# PIC18LF6393 register map
Vendor: Microchip
Architecture 18xxxx. Special function registers and configuration words.
Registers are 8-bit, read-write, no defined reset value unless marked. A register's access mark holds for its fields unless they carry their own. Addresses are absolute, and some are shared; only a register's first bit layout is shown; lines under a group give offsets from that group; [hi:lo] are bit positions; {n}, {i} and the like mark numbered series; 'fields as' and 'values as' point back to an identical list; <NAME> marks a mode.

## Further device data
pins=1: LCDBIAS2; 2: LCDBIAS1; 3: RG0/SEG30; 4: RG1/TX2/CK2/SEG29; 5: RG2/RX2/DT2/SEG28; 6: RG3/SEG27; 7: MCLR/Vpp/RG5; 8: RG4/SEG26; 9: Vss; 10: Vdd; 11: RF7/SS/SEG25; 12: RF6/AN11/SEG24; 13: RF5/AN10/CVref/SEG23; 14: RF4/AN9/SEG22; 15: RF3/AN8/SEG21; 16: RF2/AN7/C1OUT/SEG20; 17: RF1/AN6/C2OUT/SEG19; 18: RF0/AN5/SEG18; 19: AVdd; 20: AVss; 21: RA3/AN3/Vref+/SEG17; 22: RA2/AN2/Vref-/SEG16; 23: RA1/AN1; 24: RA0/AN0; 25: Vss; 26: Vdd; 27: RA5/AN4/HLVDIN/SEG15; 28: RA4/T0CKI/SEG14; 29: RC1/T1OSI/CCP2; 30: RC0/T1OSO/T13CKI; 31: RC6/TX1/CK1; 32: RC7/RX1/DT1; 33: RC2/CCP1/SEG13; 34: RC3/SCK/SCL; 35: RC4/SDI/SDA; 36: RC5/SDO/SEG12; 37: RB7/KBI3/PGD; 38: Vdd; 39: OSC1/CLKI/RA7; 40: OSC2/CLKO/RA6; 41: Vss; 42: RB6/KBI2/PGC; 43: RB5/KBI1; 44: RB4/KBI0/SEG11; 45: RB3/INT3/SEG10; 46: RB2/INT2/SEG9; 47: RB1/INT1/SEG8; 48: RB0/INT0; 49: RD7/SEG7; 50: RD6/SEG6; 51: RD5/SEG5; 52: RD4/SEG4; 53: RD3/SEG3; 54: RD2/SEG2; 55: RD1/SEG1; 56: Vss; 57: Vdd; 58: RD0/SEG0; 59: RE7/CCP2/SEG31; 60: RE6/COM3; 61: RE5/COM2; 62: RE4/COM1; 63: COM0; 64: LCDBIAS3

## CONFIG — Configuration words, addresses in ProgramSpace
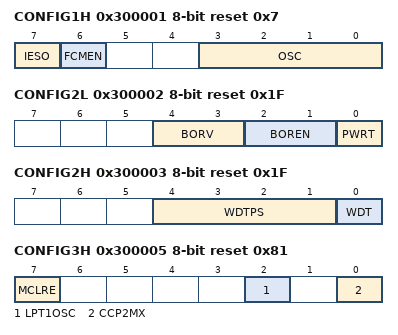
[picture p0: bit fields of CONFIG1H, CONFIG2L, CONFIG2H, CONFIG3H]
0x300001 CONFIG1H reset 0x7
  [7] IESO — Internal External Switch Over Mode
    0=OFF (Oscillator Switchover mode disabled); 1=ON (Oscillator Switchover mode enabled)
  [6] FCMEN — Fail-Safe Clock Monitor Enable
    0=OFF (Fail-Safe Clock Monitor disabled); 1=ON (Fail-Safe Clock Monitor enabled)
  [3:0] OSC — Oscillator
    0b11xx=11XX EXT RC-CLKOUT on RA6; 0b101x=101X EXT RC-CLKOUT on RA6; 9=INTIO7 (Internal oscillator block, CLKO function on RA6, port function on RA7); 8=INTIO67 (Internal oscillator block, port function on RA6 and RA7); 7=RCIO (External RC oscillator, port function on RA6); 6=HSPLL (HS oscillator, PLL enabled (clock frequency = 4 x FOSC1)); 5=ECIO (EC oscillator, port function on RA6); 4=EC (EC oscillator, CLKO function on RA6); 3=RC (External RC oscillator, CLKO function on RA6); 2=HS (HS oscillator); 1=XT (XT oscillator); 0=LP (LP oscillator)
0x300002 CONFIG2L reset 0x1F
  [4:3] BORV — Brown Out Voltage
    3=VBOR set to 2.1V; 2=VBOR set to 2.8V; 1=VBOR set to 4.3V; 0=VBOR set to 4.6V
  [2:1] BOREN — Brown Out Detect
    3=SBORDIS (Brown-out Reset enabled in hardware only (SBOREN is disabled)); 2=NOSLP (Brown-out Reset enabled in hardware only and disabled in Sleep mode (SBOREN is disabled)); 1=ON (Brown-out Reset enabled and controlled by software (SBOREN is enabled)); 0=OFF (Brown-out Reset disabled in hardware and software)
  [0] PWRT — Power Up Timer
    1=OFF (PWRT disabled); 0=ON (PWRT enabled)
0x300003 CONFIG2H reset 0x1F
  [4:1] WDTPS — Watchdog Postscaler
    15=1:32768; 14=1:16384; 13=1:8192; 12=1:4096; 11=1:2048; 10=1:1024; 9=1:512; 8=1:256; 7=1:128; 6=1:64; 5=1:32; 4=1:16; 3=1:8; 2=1:4; 1=1:2; 0=1:1
  [0] WDT — Watchdog Timer
    1=ON (WDT enabled); 0=OFF (WDT disabled (control is placed on the SWDTEN bit))
0x300004 CONFIG3L reset 0xFF
0x300005 CONFIG3H reset 0x81
  [7] MCLRE — Master Clear Enable
    1=ON (MCLR pin enabled; RG5 input pin disabled); 0=OFF (RG5 input pin enabled; MCLR disabled)
  [2] LPT1OSC — Low Power Timer1 Osc enable
    1=ON (Timer1 configured for low-power operation); 0=OFF (Timer1 configured for higher power operation)
  [0] CCP2MX — CCP2 Mux
    1=PORTC (CCP2 input/output is multiplexed with RC1); 0=PORTBE (CCP2 input/output is multiplexed with RE7)
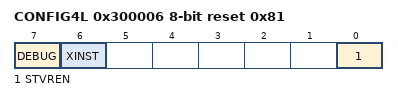
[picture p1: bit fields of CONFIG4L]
0x300006 CONFIG4L reset 0x81
  [7] DEBUG — Background Debugger Enable bit
    1=OFF (Background debugger disabled, RB6 and RB7 configured as general purpose I/O pins); 0=ON (Background debugger enabled, RB6 and RB7 are dedicated to In-Circuit Debug)
  [6] XINST — Extended Instruction Set Enable bit
    1=ON (Instruction set extension and Indexed Addressing mode enabled); 0=OFF (Instruction set extension and Indexed Addressing mode disabled (Legacy mode))
  [0] STVREN — Stack Overflow Reset
    1=ON (Stack full/underflow will cause Reset); 0=OFF (Stack full/underflow will not cause Reset)
0x300008 CONFIG5L reset 0x1
  [0] CP — Code Protect 00000-03FFF
    1=OFF (Program memory block (000000-003FFFh) not code-protected); 0=ON (Program memory block (000000-003FFFh) code-protected)
0x30000C CONFIG7L reset 0xFF
